# R7KA8D2AD register map
Vendor: Renesas Electronics Corporation; Series: RA8; File version: 1.10.02
CPU: CM85 r0p2, little endian, MPU, FPU, VTOR, 4 interrupt priority bits, 96 interrupts
Registers are 32-bit, read-write, reset 0x0 unless marked. A register's access mark holds for its fields unless they carry their own. Offsets are from the block's base; [hi:lo] are bit positions.

## CPU_DBG — Debug Function
Base 0x4001B000
Same registers: CPU_DBG_NS 0x5001B000
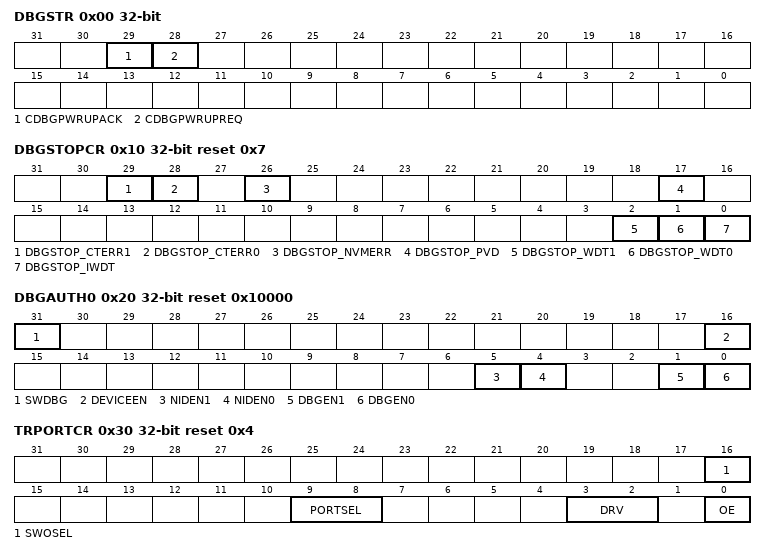
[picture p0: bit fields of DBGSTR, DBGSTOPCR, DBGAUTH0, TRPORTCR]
0x00 DBGSTR ro (reset mask 0xCFFFFFFF) — Debug Status Register
  [29] CDBGPWRUPACK — Debug power-up acknowledge
    0=Debug power-up request is not acknowledged; 1=Debug power-up request is acknowledged
  [28] CDBGPWRUPREQ — Debug power-up request
    0=OCD is not requesting debug power-up; 1=OCD is requesting debug power-up
0x10 DBGSTOPCR reset 0x7 — Debug Stop Control Register
  [29] DBGSTOP_CTERR1 — This bit is reserved. It can be R/W but has no effect.
  [28] DBGSTOP_CTERR0 — Mask bit for Cache/TCM ECC error reset of CPU0
    0=Enable Cache/TCM ECC error reset; 1=Mask Cache/TCM ECC error reset
  [26] DBGSTOP_NVMERR — Mask bit for MRAM ECC error reset/interrupt
    0=Enable MRAM ECC error reset/interrupt; 1=Mask MRAM ECC error reset/interrupt
  [17] DBGSTOP_PVD — Mask bit for PVDn (n! = 0) reset/interrupt
    0=Enable PVDn (n! = 0) reset/interrupt; 1=Mask PVDn (n! = 0) reset/interrupt
  [2] DBGSTOP_WDT1 — Mask bit for WDT1 reset/interrupt in the OCD run mode
    0=Enable WDT1 reset/interrupt; 1=Mask WDT1 reset/interrupt and stop WDT1 counter
  [1] DBGSTOP_WDT0 — Mask bit for WDT0 reset/interrupt in the OCD run mode
    0=Enable WDT0 reset/interrupt; 1=Mask WDT0 reset/interrupt and stop WDT0 counter
  [0] DBGSTOP_IWDT — Mask bit for IWDT reset/interrupt in the OCD run mode
    0=Enable IWDT reset/interrupt; 1=Mask IWDT reset/interrupt and stop IWDT counter
0x20 DBGAUTH0 reset 0x10000 (reset mask 0x7FFFFFFF) — Debug Authentication Control Register0
  [all] fields
    0=Disabled; 1=Enabled
  [31] SWDBG ro — Software control of debug function
  [16] DEVICEEN — APB-AP (AP1) authentication
  [5] NIDEN1 — CPU1 non-invasive debug enable
  [4] NIDEN0 — CPU0 non-invasive debug enable
  [1] DBGEN1 — CPU1 invasive debug enable
  [0] DBGEN0 — CPU0 invasive debug enable
0x30 TRPORTCR reset 0x4 — Trace Port Control Register
  [16] SWOSEL — Select SWO between CPU0 and CPU1
    0=SWO of CPU0 is selected (default); 1=SWO of CPU1 is selected
  [9:8] PORTSEL — Port select. Only A port setting is supported.
    0=A port; 1=B port
  [3:2] DRV — Port drive capability control indicates trace port buffer speed.
    0=Low; 1=Middle; 2=High-Speed high-drive; 3=High
  [0] OE — OE bit should be enabled before trace clock is enabled.
    0=Output disabled; 1=Output enabled
0x38 TRPORTSZ reset 0x1 — Trace Port Size Control Register
  [31:0] PORTSIZE — Indicates how many pins of TRACEDATA are available.
0x40 CACHEDBGCR — Cache Debug Control Register
  [0] L1RSTDIS — Disable L1 cache automatic invalidation of CPU0
    0=Enable automatic invalidation of the L1 cache; 1=Disable automatic invalidation of the L1 cache
0x50 DBGNVMCR — Debug Non-volatile Memory Control Register
  [0] NVMWE — Non-volatile memory write enable
    0=MRAM write is not allowed; 1=MRAM write is allowed
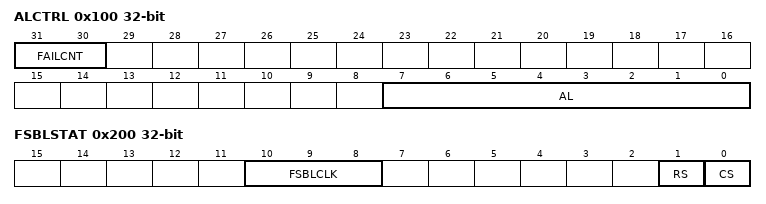
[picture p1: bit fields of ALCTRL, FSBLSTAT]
0x100 ALCTRL (reset mask 0xFFFFFF00) — Authentication Level Control Register
  [31:30] FAILCNT — Number of times responding to incorrect response data
    0=No responding to incorrect response data; 1=First time of responding to incorrect response data; 2=Second time of responding to incorrect response data; 3=Third time of responding to incorrect response data
  [7:0] AL — AL monitor
    0=AL0; 5=AL1; 165=AL2
0x200 FSBLSTAT — First Stage Boot Loader Status Register
  [10:8] FSBLCLK ro — System clock frequency selection during FSBL execution
  [1] RS — FSBL result status
    0=FSBL failed; 1=FSBL passed
  [0] CS — FSBL completion status
    0=FSBL is executing; 1=FSBL execution is complete
